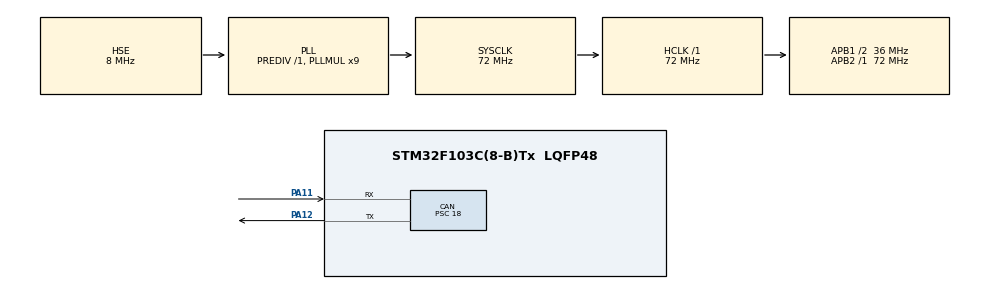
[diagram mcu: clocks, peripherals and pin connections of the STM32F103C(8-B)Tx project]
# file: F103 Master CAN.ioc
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CAN.BS1=CAN_BS1_2TQ
CAN.CalculateBaudRate=500000
CAN.CalculateTimeBit=2000
CAN.CalculateTimeQuantum=500.0
CAN.Mode=CAN_MODE_NORMAL
CAN.NART=ENABLE
CAN.Prescaler=18
CAN.RFLM=ENABLE
CAN.SJW=CAN_SJW_1TQ
Mcu.Family=STM32F1
Mcu.Name=STM32F103C(8-B)Tx
Mcu.Package=LQFP48
NVIC.CAN1_RX1_IRQn=true\:0\:0\:false\:false\:true\:true\:true\:true
NVIC.PriorityGroup=NVIC_PRIORITYGROUP_4
NVIC.USB_LP_CAN1_RX0_IRQn=true\:0\:0\:false\:false\:true\:true\:true\:true
PA11.Mode=CAN_Activate
PA11.Signal=CAN_RX
PA12.Mode=CAN_Activate
PA12.Signal=CAN_TX
PA13.Mode=Serial_Wire
PA13.Signal=SYS_JTMS-SWDIO
PA14.Mode=Serial_Wire
PA14.Signal=SYS_JTCK-SWCLK
PD0-OSC_IN.Mode=HSE-External-Oscillator
PD0-OSC_IN.Signal=RCC_OSC_IN
PD1-OSC_OUT.Mode=HSE-External-Oscillator
PD1-OSC_OUT.Signal=RCC_OSC_OUT
ProjectManager.HeapSize=0x200
ProjectManager.StackSize=0x400
ProjectManager.TargetToolchain=MDK-ARM V5.32
RCC.AHBFreq_Value=72000000
RCC.APB1CLKDivider=RCC_HCLK_DIV2
RCC.APB1Freq_Value=36000000
RCC.APB1TimFreq_Value=72000000
RCC.APB2Freq_Value=72000000
RCC.APB2TimFreq_Value=72000000
RCC.HCLKFreq_Value=72000000
RCC.PLLMUL=RCC_PLL_MUL9
RCC.PLLSourceVirtual=RCC_PLLSOURCE_HSE
RCC.SYSCLKFreq_VALUE=72000000
RCC.SYSCLKSource=RCC_SYSCLKSOURCE_PLLCLK
RCC.USBFreq_Value=72000000
board=custom

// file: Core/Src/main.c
/* USER CODE BEGIN Header */
/**
  ******************************************************************************
  * @file           : main.c
  * @brief          : Main program body
  ******************************************************************************
  * @attention
  *
  * <h2><center>&copy; Copyright (c) 2021 STMicroelectronics.
  * All rights reserved.</center></h2>
  *
  * This software component is licensed by ST under BSD 3-Clause license,
  * the "License"; You may not use this file except in compliance with the
  * License. You may obtain a copy of the License at:
  *                        opensource.org/licenses/BSD-3-Clause
  *
  ******************************************************************************
  */
/* USER CODE END Header */
#include "main.h"

/* USER CODE BEGIN Includes */
#include "Canbus.h"

/* USER CODE END Includes */

CAN_HandleTypeDef hcan;

void SystemClock_Config(void);
static void MX_GPIO_Init(void);
static void MX_CAN_Init(void);

/* USER CODE BEGIN 0 */
uint32_t time;

CAN_SensorTypeDef 	Encoder;
CAN_SensorTypeDef		IMU;
CAN_FIFO_RxTypeDef	Fifo1_Rx;

float x_pos;
float y_pos;
float x_ang;
float y_ang;
float z_ang;

CAN_FilterTypeDef can_filter;

void HAL_CAN_RxFifo1MsgPendingCallback(CAN_HandleTypeDef *hcan)
{
	CAN_Fifo_RxFlag(hcan, CAN_RX_FIFO1, &Fifo1_Rx);
	CAN_Sensor_RecieveFb(&Fifo1_Rx, &Encoder);
	CAN_Sensor_RecieveFb(&Fifo1_Rx, &IMU);
}

/* USER CODE END 0 */

int main(void)
{

  /* MCU Configuration--------------------------------------------------------*/

  /* Reset of all peripherals, Initializes the Flash interface and the Systick. */
  HAL_Init();

  /* Configure the system clock */
  SystemClock_Config();

  /* Initialize all configured peripherals */
  MX_GPIO_Init();
  MX_CAN_Init();
  /* USER CODE BEGIN 2 */

  HAL_CAN_Start(&hcan);
	//Khoi tao header
	CAN_Sensor_TxHeader_Init(&Encoder, ENC_SID, ENC_FBID, ENC_TXID, ENC_RSID);
	CAN_Sensor_TxHeader_Init(&IMU, IMU_SID, IMU_FBID, IMU_TXID, IMU_RSID);
	//Bat ngat ngoai khi nhan data
	HAL_CAN_ActivateNotification(&hcan, CAN_IT_RX_FIFO1_MSG_PENDING);
	//Tao CAN Filter
	CAN_Filter_Config(&hcan, &can_filter, 0, CAN_RX_FIFO1, MAS_FILID, MAS_FILIDM);
	//Bat dau encoder voi tan sô gui lenh là 200Hz
	CAN_Sensor_Start(&hcan, 200, &Encoder);
	//Bat dau IMU voi tan so gui lenh là 500Hz
	CAN_Sensor_Start(&hcan, 500, &IMU);

  /* USER CODE END 2 */

  /* Infinite loop */
  while (1)
  {

    /* USER CODE BEGIN 3 */
		//Nhân du lieu tu Slave
		CAN_Float_RxData(&Fifo1_Rx, &Encoder, &x_pos, X_POS_ADDR);
		CAN_Float_RxData(&Fifo1_Rx, &Encoder, &y_pos, Y_POS_ADDR);
		CAN_Float_RxData(&Fifo1_Rx, &IMU, &x_ang, X_ANG_ADDR);
		CAN_Float_RxData(&Fifo1_Rx, &IMU, &y_ang, Y_ANG_ADDR);
		CAN_Float_RxData(&Fifo1_Rx, &IMU, &z_ang, Z_ANG_ADDR);
		//Reset Sensor vè môc 0 môi 20s
		if ((HAL_GetTick() - time) >= 20000)
		{
			CAN_Sensor_ResetRQ(&hcan, &Encoder);
			CAN_Sensor_ResetRQ(&hcan, &IMU);
			time = HAL_GetTick();
		}

  }
  /* USER CODE END 3 */
}

void SystemClock_Config(void)
{
  RCC_OscInitTypeDef RCC_OscInitStruct = {0};
  RCC_ClkInitTypeDef RCC_ClkInitStruct = {0};

  /** Initializes the RCC Oscillators according to the specified parameters
  * in the RCC_OscInitTypeDef structure.
  */
  RCC_OscInitStruct.OscillatorType = RCC_OSCILLATORTYPE_HSE;
  RCC_OscInitStruct.HSEState = RCC_HSE_ON;
  RCC_OscInitStruct.HSEPredivValue = RCC_HSE_PREDIV_DIV1;
  RCC_OscInitStruct.HSIState = RCC_HSI_ON;
  RCC_OscInitStruct.PLL.PLLState = RCC_PLL_ON;
  RCC_OscInitStruct.PLL.PLLSource = RCC_PLLSOURCE_HSE;
  RCC_OscInitStruct.PLL.PLLMUL = RCC_PLL_MUL9;
  if (HAL_RCC_OscConfig(&RCC_OscInitStruct) != HAL_OK)
  {
    Error_Handler();
  }

  /** Initializes the CPU, AHB and APB buses clocks
  */
  RCC_ClkInitStruct.ClockType = RCC_CLOCKTYPE_HCLK|RCC_CLOCKTYPE_SYSCLK
                              |RCC_CLOCKTYPE_PCLK1|RCC_CLOCKTYPE_PCLK2;
  RCC_ClkInitStruct.SYSCLKSource = RCC_SYSCLKSOURCE_PLLCLK;
  RCC_ClkInitStruct.AHBCLKDivider = RCC_SYSCLK_DIV1;
  RCC_ClkInitStruct.APB1CLKDivider = RCC_HCLK_DIV2;
  RCC_ClkInitStruct.APB2CLKDivider = RCC_HCLK_DIV1;

  if (HAL_RCC_ClockConfig(&RCC_ClkInitStruct, FLASH_LATENCY_2) != HAL_OK)
  {
    Error_Handler();
  }
}

static void MX_CAN_Init(void)
{

  hcan.Instance = CAN1;
  hcan.Init.Prescaler = 18;
  hcan.Init.Mode = CAN_MODE_NORMAL;
  hcan.Init.SyncJumpWidth = CAN_SJW_1TQ;
  hcan.Init.TimeSeg1 = CAN_BS1_2TQ;
  hcan.Init.TimeSeg2 = CAN_BS2_1TQ;
  hcan.Init.TimeTriggeredMode = DISABLE;
  hcan.Init.AutoBusOff = DISABLE;
  hcan.Init.AutoWakeUp = DISABLE;
  hcan.Init.AutoRetransmission = ENABLE;
  hcan.Init.ReceiveFifoLocked = ENABLE;
  hcan.Init.TransmitFifoPriority = DISABLE;
  if (HAL_CAN_Init(&hcan) != HAL_OK)
  {
    Error_Handler();
  }

}

static void MX_GPIO_Init(void)
{

  /* GPIO Ports Clock Enable */
  __HAL_RCC_GPIOD_CLK_ENABLE();
  __HAL_RCC_GPIOA_CLK_ENABLE();

}

void Error_Handler(void)
{
  __disable_irq();
  while (1)
  {
  }
}
